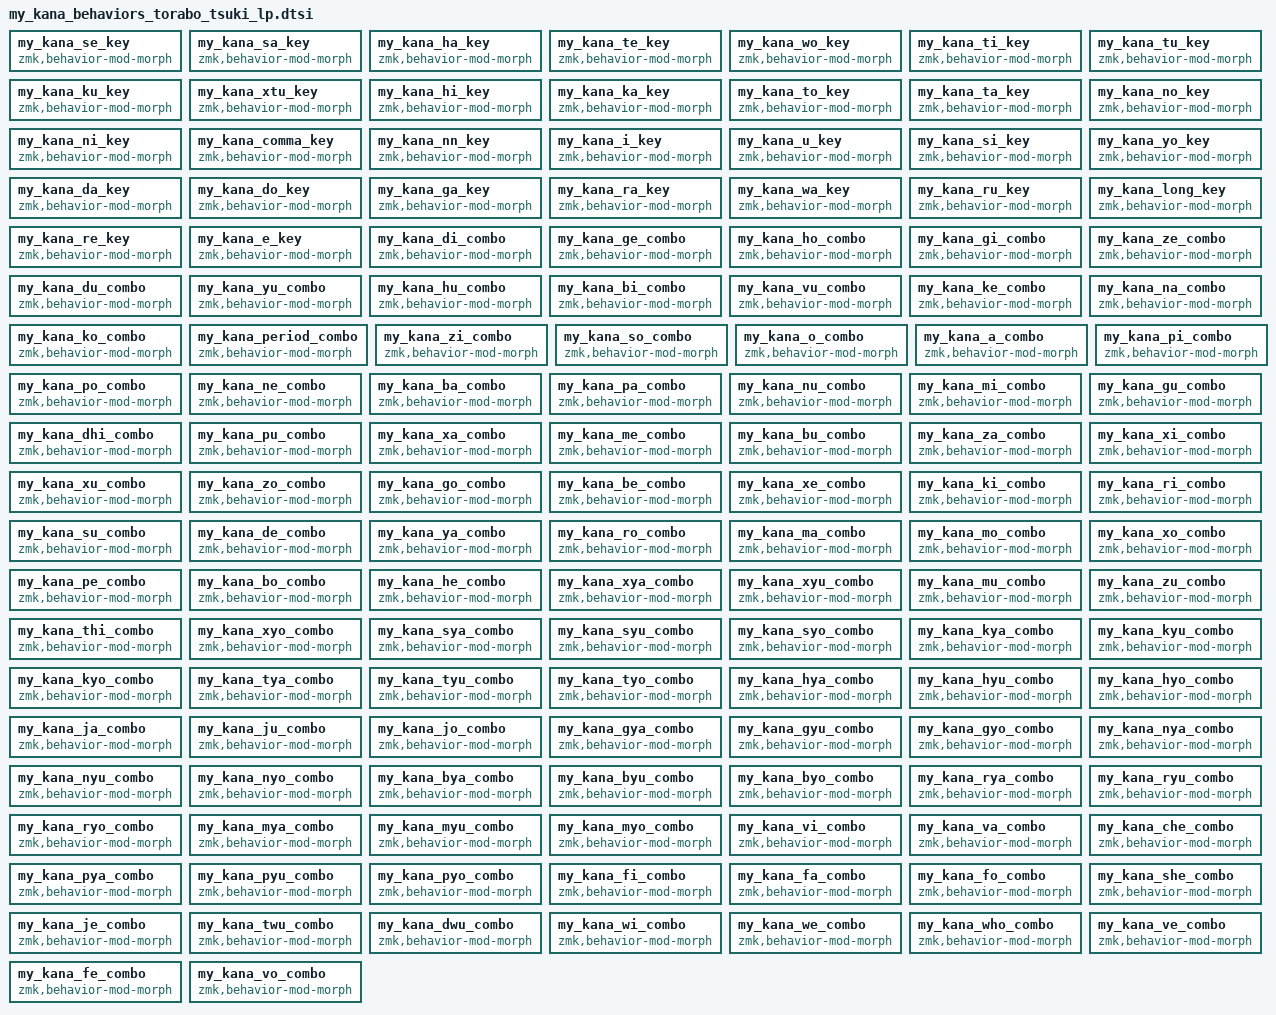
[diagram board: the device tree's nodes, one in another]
// Generated by tools/generate_my_kana_zmk.py. Do not edit manually.

        my_kana_se_key: my_kana_se_key {
            compatible = "zmk,behavior-mod-morph";
            #binding-cells = <0>;
            bindings = <&my_kana_se>, <&kp Q>;
            mods = <MY_KANA_MODS>;
            keep-mods = <MY_KANA_MODS>;
        };

        my_kana_sa_key: my_kana_sa_key {
            compatible = "zmk,behavior-mod-morph";
            #binding-cells = <0>;
            bindings = <&my_kana_sa>, <&kp W>;
            mods = <MY_KANA_MODS>;
            keep-mods = <MY_KANA_MODS>;
        };

        my_kana_ha_key: my_kana_ha_key {
            compatible = "zmk,behavior-mod-morph";
            #binding-cells = <0>;
            bindings = <&my_kana_ha>, <&kp E>;
            mods = <MY_KANA_MODS>;
            keep-mods = <MY_KANA_MODS>;
        };

        my_kana_te_key: my_kana_te_key {
            compatible = "zmk,behavior-mod-morph";
            #binding-cells = <0>;
            bindings = <&my_kana_te>, <&kp R>;
            mods = <MY_KANA_MODS>;
            keep-mods = <MY_KANA_MODS>;
        };

        my_kana_wo_key: my_kana_wo_key {
            compatible = "zmk,behavior-mod-morph";
            #binding-cells = <0>;
            bindings = <&my_kana_wo>, <&kp T>;
            mods = <MY_KANA_MODS>;
            keep-mods = <MY_KANA_MODS>;
        };

        my_kana_ti_key: my_kana_ti_key {
            compatible = "zmk,behavior-mod-morph";
            #binding-cells = <0>;
            bindings = <&my_kana_ti>, <&kp Y>;
            mods = <MY_KANA_MODS>;
            keep-mods = <MY_KANA_MODS>;
        };

        my_kana_tu_key: my_kana_tu_key {
            compatible = "zmk,behavior-mod-morph";
            #binding-cells = <0>;
            bindings = <&my_kana_tu>, <&kp U>;
            mods = <MY_KANA_MODS>;
            keep-mods = <MY_KANA_MODS>;
        };

        my_kana_ku_key: my_kana_ku_key {
            compatible = "zmk,behavior-mod-morph";
            #binding-cells = <0>;
            bindings = <&my_kana_ku>, <&kp I>;
            mods = <MY_KANA_MODS>;
            keep-mods = <MY_KANA_MODS>;
        };

        my_kana_xtu_key: my_kana_xtu_key {
            compatible = "zmk,behavior-mod-morph";
            #binding-cells = <0>;
            bindings = <&my_kana_xtu>, <&kp O>;
            mods = <MY_KANA_MODS>;
            keep-mods = <MY_KANA_MODS>;
        };

        my_kana_hi_key: my_kana_hi_key {
            compatible = "zmk,behavior-mod-morph";
            #binding-cells = <0>;
            bindings = <&my_kana_hi>, <&kp P>;
            mods = <MY_KANA_MODS>;
            keep-mods = <MY_KANA_MODS>;
        };

        my_kana_ka_key: my_kana_ka_key {
            compatible = "zmk,behavior-mod-morph";
            #binding-cells = <0>;
            bindings = <&my_kana_ka>, <&kp A>;
            mods = <MY_KANA_MODS>;
            keep-mods = <MY_KANA_MODS>;
        };

        my_kana_to_key: my_kana_to_key {
            compatible = "zmk,behavior-mod-morph";
            #binding-cells = <0>;
            bindings = <&my_kana_to>, <&kp S>;
            mods = <MY_KANA_MODS>;
            keep-mods = <MY_KANA_MODS>;
        };

        my_kana_ta_key: my_kana_ta_key {
            compatible = "zmk,behavior-mod-morph";
            #binding-cells = <0>;
            bindings = <&my_kana_ta>, <&kp D>;
            mods = <MY_KANA_MODS>;
            keep-mods = <MY_KANA_MODS>;
        };

        my_kana_no_key: my_kana_no_key {
            compatible = "zmk,behavior-mod-morph";
            #binding-cells = <0>;
            bindings = <&my_kana_no>, <&kp F>;
            mods = <MY_KANA_MODS>;
            keep-mods = <MY_KANA_MODS>;
        };

        my_kana_ni_key: my_kana_ni_key {
            compatible = "zmk,behavior-mod-morph";
            #binding-cells = <0>;
            bindings = <&my_kana_ni>, <&kp G>;
            mods = <MY_KANA_MODS>;
            keep-mods = <MY_KANA_MODS>;
        };

        my_kana_comma_key: my_kana_comma_key {
            compatible = "zmk,behavior-mod-morph";
            #binding-cells = <0>;
            bindings = <&my_kana_comma>, <&kp H>;
            mods = <MY_KANA_MODS>;
            keep-mods = <MY_KANA_MODS>;
        };

        my_kana_nn_key: my_kana_nn_key {
            compatible = "zmk,behavior-mod-morph";
            #binding-cells = <0>;
            bindings = <&my_kana_nn>, <&kp J>;
            mods = <MY_KANA_MODS>;
            keep-mods = <MY_KANA_MODS>;
        };

        my_kana_i_key: my_kana_i_key {
            compatible = "zmk,behavior-mod-morph";
            #binding-cells = <0>;
            bindings = <&my_kana_i>, <&kp K>;
            mods = <MY_KANA_MODS>;
            keep-mods = <MY_KANA_MODS>;
        };

        my_kana_u_key: my_kana_u_key {
            compatible = "zmk,behavior-mod-morph";
            #binding-cells = <0>;
            bindings = <&my_kana_u>, <&kp L>;
            mods = <MY_KANA_MODS>;
            keep-mods = <MY_KANA_MODS>;
        };

        my_kana_si_key: my_kana_si_key {
            compatible = "zmk,behavior-mod-morph";
            #binding-cells = <0>;
            bindings = <&my_kana_si>, <&kp SEMI>;
            mods = <MY_KANA_MODS>;
            keep-mods = <MY_KANA_MODS>;
        };

        my_kana_yo_key: my_kana_yo_key {
            compatible = "zmk,behavior-mod-morph";
            #binding-cells = <0>;
            bindings = <&my_kana_yo>, <&kp Z>;
            mods = <MY_KANA_MODS>;
            keep-mods = <MY_KANA_MODS>;
        };

        my_kana_da_key: my_kana_da_key {
            compatible = "zmk,behavior-mod-morph";
            #binding-cells = <0>;
            bindings = <&my_kana_da>, <&kp X>;
            mods = <MY_KANA_MODS>;
            keep-mods = <MY_KANA_MODS>;
        };

        my_kana_do_key: my_kana_do_key {
            compatible = "zmk,behavior-mod-morph";
            #binding-cells = <0>;
            bindings = <&my_kana_do>, <&kp C>;
            mods = <MY_KANA_MODS>;
            keep-mods = <MY_KANA_MODS>;
        };

        my_kana_ga_key: my_kana_ga_key {
            compatible = "zmk,behavior-mod-morph";
            #binding-cells = <0>;
            bindings = <&my_kana_ga>, <&kp V>;
            mods = <MY_KANA_MODS>;
            keep-mods = <MY_KANA_MODS>;
        };

        my_kana_ra_key: my_kana_ra_key {
            compatible = "zmk,behavior-mod-morph";
            #binding-cells = <0>;
            bindings = <&my_kana_ra>, <&kp B>;
            mods = <MY_KANA_MODS>;
            keep-mods = <MY_KANA_MODS>;
        };

        my_kana_wa_key: my_kana_wa_key {
            compatible = "zmk,behavior-mod-morph";
            #binding-cells = <0>;
            bindings = <&my_kana_wa>, <&kp N>;
            mods = <MY_KANA_MODS>;
            keep-mods = <MY_KANA_MODS>;
        };

        my_kana_ru_key: my_kana_ru_key {
            compatible = "zmk,behavior-mod-morph";
            #binding-cells = <0>;
            bindings = <&my_kana_ru>, <&kp M>;
            mods = <MY_KANA_MODS>;
            keep-mods = <MY_KANA_MODS>;
        };

        my_kana_long_key: my_kana_long_key {
            compatible = "zmk,behavior-mod-morph";
            #binding-cells = <0>;
            bindings = <&my_kana_long>, <&kp COMMA>;
            mods = <MY_KANA_MODS>;
            keep-mods = <MY_KANA_MODS>;
        };

        my_kana_re_key: my_kana_re_key {
            compatible = "zmk,behavior-mod-morph";
            #binding-cells = <0>;
            bindings = <&my_kana_re>, <&kp DOT>;
            mods = <MY_KANA_MODS>;
            keep-mods = <MY_KANA_MODS>;
        };

        my_kana_e_key: my_kana_e_key {
            compatible = "zmk,behavior-mod-morph";
            #binding-cells = <0>;
            bindings = <&my_kana_e>, <&kp SLASH>;
            mods = <MY_KANA_MODS>;
            keep-mods = <MY_KANA_MODS>;
        };

        my_kana_di_combo: my_kana_di_combo {
            compatible = "zmk,behavior-mod-morph";
            #binding-cells = <0>;
            bindings = <&my_kana_di>, <&my_kana_di_pass>;
            mods = <MY_KANA_MODS>;
            keep-mods = <MY_KANA_MODS>;
        };

        my_kana_ge_combo: my_kana_ge_combo {
            compatible = "zmk,behavior-mod-morph";
            #binding-cells = <0>;
            bindings = <&my_kana_ge>, <&my_kana_ge_pass>;
            mods = <MY_KANA_MODS>;
            keep-mods = <MY_KANA_MODS>;
        };

        my_kana_ho_combo: my_kana_ho_combo {
            compatible = "zmk,behavior-mod-morph";
            #binding-cells = <0>;
            bindings = <&my_kana_ho>, <&my_kana_ho_pass>;
            mods = <MY_KANA_MODS>;
            keep-mods = <MY_KANA_MODS>;
        };

        my_kana_gi_combo: my_kana_gi_combo {
            compatible = "zmk,behavior-mod-morph";
            #binding-cells = <0>;
            bindings = <&my_kana_gi>, <&my_kana_gi_pass>;
            mods = <MY_KANA_MODS>;
            keep-mods = <MY_KANA_MODS>;
        };

        my_kana_ze_combo: my_kana_ze_combo {
            compatible = "zmk,behavior-mod-morph";
            #binding-cells = <0>;
            bindings = <&my_kana_ze>, <&my_kana_ze_pass>;
            mods = <MY_KANA_MODS>;
            keep-mods = <MY_KANA_MODS>;
        };

        my_kana_du_combo: my_kana_du_combo {
            compatible = "zmk,behavior-mod-morph";
            #binding-cells = <0>;
            bindings = <&my_kana_du>, <&my_kana_du_pass>;
            mods = <MY_KANA_MODS>;
            keep-mods = <MY_KANA_MODS>;
        };

        my_kana_yu_combo: my_kana_yu_combo {
            compatible = "zmk,behavior-mod-morph";
            #binding-cells = <0>;
            bindings = <&my_kana_yu>, <&my_kana_yu_pass>;
            mods = <MY_KANA_MODS>;
            keep-mods = <MY_KANA_MODS>;
        };

        my_kana_hu_combo: my_kana_hu_combo {
            compatible = "zmk,behavior-mod-morph";
            #binding-cells = <0>;
            bindings = <&my_kana_hu>, <&my_kana_hu_pass>;
            mods = <MY_KANA_MODS>;
            keep-mods = <MY_KANA_MODS>;
        };

        my_kana_bi_combo: my_kana_bi_combo {
            compatible = "zmk,behavior-mod-morph";
            #binding-cells = <0>;
            bindings = <&my_kana_bi>, <&my_kana_bi_pass>;
            mods = <MY_KANA_MODS>;
            keep-mods = <MY_KANA_MODS>;
        };

        my_kana_vu_combo: my_kana_vu_combo {
            compatible = "zmk,behavior-mod-morph";
            #binding-cells = <0>;
            bindings = <&my_kana_vu>, <&my_kana_vu_pass>;
            mods = <MY_KANA_MODS>;
            keep-mods = <MY_KANA_MODS>;
        };

        my_kana_ke_combo: my_kana_ke_combo {
            compatible = "zmk,behavior-mod-morph";
            #binding-cells = <0>;
            bindings = <&my_kana_ke>, <&my_kana_ke_pass>;
            mods = <MY_KANA_MODS>;
            keep-mods = <MY_KANA_MODS>;
        };

        my_kana_na_combo: my_kana_na_combo {
            compatible = "zmk,behavior-mod-morph";
            #binding-cells = <0>;
            bindings = <&my_kana_na>, <&my_kana_na_pass>;
            mods = <MY_KANA_MODS>;
            keep-mods = <MY_KANA_MODS>;
        };

        my_kana_ko_combo: my_kana_ko_combo {
            compatible = "zmk,behavior-mod-morph";
            #binding-cells = <0>;
            bindings = <&my_kana_ko>, <&my_kana_ko_pass>;
            mods = <MY_KANA_MODS>;
            keep-mods = <MY_KANA_MODS>;
        };

        my_kana_period_combo: my_kana_period_combo {
            compatible = "zmk,behavior-mod-morph";
            #binding-cells = <0>;
            bindings = <&my_kana_period>, <&my_kana_period_pass>;
            mods = <MY_KANA_MODS>;
            keep-mods = <MY_KANA_MODS>;
        };

        my_kana_zi_combo: my_kana_zi_combo {
            compatible = "zmk,behavior-mod-morph";
            #binding-cells = <0>;
            bindings = <&my_kana_zi>, <&my_kana_zi_pass>;
            mods = <MY_KANA_MODS>;
            keep-mods = <MY_KANA_MODS>;
        };

        my_kana_so_combo: my_kana_so_combo {
            compatible = "zmk,behavior-mod-morph";
            #binding-cells = <0>;
            bindings = <&my_kana_so>, <&my_kana_so_pass>;
            mods = <MY_KANA_MODS>;
            keep-mods = <MY_KANA_MODS>;
        };

        my_kana_o_combo: my_kana_o_combo {
            compatible = "zmk,behavior-mod-morph";
            #binding-cells = <0>;
            bindings = <&my_kana_o>, <&my_kana_o_pass>;
            mods = <MY_KANA_MODS>;
            keep-mods = <MY_KANA_MODS>;
        };

        my_kana_a_combo: my_kana_a_combo {
            compatible = "zmk,behavior-mod-morph";
            #binding-cells = <0>;
            bindings = <&my_kana_a>, <&my_kana_a_pass>;
            mods = <MY_KANA_MODS>;
            keep-mods = <MY_KANA_MODS>;
        };

        my_kana_pi_combo: my_kana_pi_combo {
            compatible = "zmk,behavior-mod-morph";
            #binding-cells = <0>;
            bindings = <&my_kana_pi>, <&my_kana_pi_pass>;
            mods = <MY_KANA_MODS>;
            keep-mods = <MY_KANA_MODS>;
        };

        my_kana_po_combo: my_kana_po_combo {
            compatible = "zmk,behavior-mod-morph";
            #binding-cells = <0>;
            bindings = <&my_kana_po>, <&my_kana_po_pass>;
            mods = <MY_KANA_MODS>;
            keep-mods = <MY_KANA_MODS>;
        };

        my_kana_ne_combo: my_kana_ne_combo {
            compatible = "zmk,behavior-mod-morph";
            #binding-cells = <0>;
            bindings = <&my_kana_ne>, <&my_kana_ne_pass>;
            mods = <MY_KANA_MODS>;
            keep-mods = <MY_KANA_MODS>;
        };

        my_kana_ba_combo: my_kana_ba_combo {
            compatible = "zmk,behavior-mod-morph";
            #binding-cells = <0>;
            bindings = <&my_kana_ba>, <&my_kana_ba_pass>;
            mods = <MY_KANA_MODS>;
            keep-mods = <MY_KANA_MODS>;
        };

        my_kana_pa_combo: my_kana_pa_combo {
            compatible = "zmk,behavior-mod-morph";
            #binding-cells = <0>;
            bindings = <&my_kana_pa>, <&my_kana_pa_pass>;
            mods = <MY_KANA_MODS>;
            keep-mods = <MY_KANA_MODS>;
        };

        my_kana_nu_combo: my_kana_nu_combo {
            compatible = "zmk,behavior-mod-morph";
            #binding-cells = <0>;
            bindings = <&my_kana_nu>, <&my_kana_nu_pass>;
            mods = <MY_KANA_MODS>;
            keep-mods = <MY_KANA_MODS>;
        };

        my_kana_mi_combo: my_kana_mi_combo {
            compatible = "zmk,behavior-mod-morph";
            #binding-cells = <0>;
            bindings = <&my_kana_mi>, <&my_kana_mi_pass>;
            mods = <MY_KANA_MODS>;
            keep-mods = <MY_KANA_MODS>;
        };

        my_kana_gu_combo: my_kana_gu_combo {
            compatible = "zmk,behavior-mod-morph";
            #binding-cells = <0>;
            bindings = <&my_kana_gu>, <&my_kana_gu_pass>;
            mods = <MY_KANA_MODS>;
            keep-mods = <MY_KANA_MODS>;
        };

        my_kana_dhi_combo: my_kana_dhi_combo {
            compatible = "zmk,behavior-mod-morph";
            #binding-cells = <0>;
            bindings = <&my_kana_dhi>, <&my_kana_dhi_pass>;
            mods = <MY_KANA_MODS>;
            keep-mods = <MY_KANA_MODS>;
        };

        my_kana_pu_combo: my_kana_pu_combo {
            compatible = "zmk,behavior-mod-morph";
            #binding-cells = <0>;
            bindings = <&my_kana_pu>, <&my_kana_pu_pass>;
            mods = <MY_KANA_MODS>;
            keep-mods = <MY_KANA_MODS>;
        };

        my_kana_xa_combo: my_kana_xa_combo {
            compatible = "zmk,behavior-mod-morph";
            #binding-cells = <0>;
            bindings = <&my_kana_xa>, <&my_kana_xa_pass>;
            mods = <MY_KANA_MODS>;
            keep-mods = <MY_KANA_MODS>;
        };

        my_kana_me_combo: my_kana_me_combo {
            compatible = "zmk,behavior-mod-morph";
            #binding-cells = <0>;
            bindings = <&my_kana_me>, <&my_kana_me_pass>;
            mods = <MY_KANA_MODS>;
            keep-mods = <MY_KANA_MODS>;
        };

        my_kana_bu_combo: my_kana_bu_combo {
            compatible = "zmk,behavior-mod-morph";
            #binding-cells = <0>;
            bindings = <&my_kana_bu>, <&my_kana_bu_pass>;
            mods = <MY_KANA_MODS>;
            keep-mods = <MY_KANA_MODS>;
        };

        my_kana_za_combo: my_kana_za_combo {
            compatible = "zmk,behavior-mod-morph";
            #binding-cells = <0>;
            bindings = <&my_kana_za>, <&my_kana_za_pass>;
            mods = <MY_KANA_MODS>;
            keep-mods = <MY_KANA_MODS>;
        };

        my_kana_xi_combo: my_kana_xi_combo {
            compatible = "zmk,behavior-mod-morph";
            #binding-cells = <0>;
            bindings = <&my_kana_xi>, <&my_kana_xi_pass>;
            mods = <MY_KANA_MODS>;
            keep-mods = <MY_KANA_MODS>;
        };

        my_kana_xu_combo: my_kana_xu_combo {
            compatible = "zmk,behavior-mod-morph";
            #binding-cells = <0>;
            bindings = <&my_kana_xu>, <&my_kana_xu_pass>;
            mods = <MY_KANA_MODS>;
            keep-mods = <MY_KANA_MODS>;
        };

        my_kana_zo_combo: my_kana_zo_combo {
            compatible = "zmk,behavior-mod-morph";
            #binding-cells = <0>;
            bindings = <&my_kana_zo>, <&my_kana_zo_pass>;
            mods = <MY_KANA_MODS>;
            keep-mods = <MY_KANA_MODS>;
        };

        my_kana_go_combo: my_kana_go_combo {
            compatible = "zmk,behavior-mod-morph";
            #binding-cells = <0>;
            bindings = <&my_kana_go>, <&my_kana_go_pass>;
            mods = <MY_KANA_MODS>;
            keep-mods = <MY_KANA_MODS>;
        };

        my_kana_be_combo: my_kana_be_combo {
            compatible = "zmk,behavior-mod-morph";
            #binding-cells = <0>;
            bindings = <&my_kana_be>, <&my_kana_be_pass>;
            mods = <MY_KANA_MODS>;
            keep-mods = <MY_KANA_MODS>;
        };

        my_kana_xe_combo: my_kana_xe_combo {
            compatible = "zmk,behavior-mod-morph";
            #binding-cells = <0>;
            bindings = <&my_kana_xe>, <&my_kana_xe_pass>;
            mods = <MY_KANA_MODS>;
            keep-mods = <MY_KANA_MODS>;
        };

        my_kana_ki_combo: my_kana_ki_combo {
            compatible = "zmk,behavior-mod-morph";
            #binding-cells = <0>;
            bindings = <&my_kana_ki>, <&my_kana_ki_pass>;
            mods = <MY_KANA_MODS>;
            keep-mods = <MY_KANA_MODS>;
        };

        my_kana_ri_combo: my_kana_ri_combo {
            compatible = "zmk,behavior-mod-morph";
            #binding-cells = <0>;
            bindings = <&my_kana_ri>, <&my_kana_ri_pass>;
            mods = <MY_KANA_MODS>;
            keep-mods = <MY_KANA_MODS>;
        };

        my_kana_su_combo: my_kana_su_combo {
            compatible = "zmk,behavior-mod-morph";
            #binding-cells = <0>;
            bindings = <&my_kana_su>, <&my_kana_su_pass>;
            mods = <MY_KANA_MODS>;
            keep-mods = <MY_KANA_MODS>;
        };

        my_kana_de_combo: my_kana_de_combo {
            compatible = "zmk,behavior-mod-morph";
            #binding-cells = <0>;
            bindings = <&my_kana_de>, <&my_kana_de_pass>;
            mods = <MY_KANA_MODS>;
            keep-mods = <MY_KANA_MODS>;
        };

        my_kana_ya_combo: my_kana_ya_combo {
            compatible = "zmk,behavior-mod-morph";
            #binding-cells = <0>;
            bindings = <&my_kana_ya>, <&my_kana_ya_pass>;
            mods = <MY_KANA_MODS>;
            keep-mods = <MY_KANA_MODS>;
        };

        my_kana_ro_combo: my_kana_ro_combo {
            compatible = "zmk,behavior-mod-morph";
            #binding-cells = <0>;
            bindings = <&my_kana_ro>, <&my_kana_ro_pass>;
            mods = <MY_KANA_MODS>;
            keep-mods = <MY_KANA_MODS>;
        };

        my_kana_ma_combo: my_kana_ma_combo {
            compatible = "zmk,behavior-mod-morph";
            #binding-cells = <0>;
            bindings = <&my_kana_ma>, <&my_kana_ma_pass>;
            mods = <MY_KANA_MODS>;
            keep-mods = <MY_KANA_MODS>;
        };

        my_kana_mo_combo: my_kana_mo_combo {
            compatible = "zmk,behavior-mod-morph";
            #binding-cells = <0>;
            bindings = <&my_kana_mo>, <&my_kana_mo_pass>;
            mods = <MY_KANA_MODS>;
            keep-mods = <MY_KANA_MODS>;
        };

        my_kana_xo_combo: my_kana_xo_combo {
            compatible = "zmk,behavior-mod-morph";
            #binding-cells = <0>;
            bindings = <&my_kana_xo>, <&my_kana_xo_pass>;
            mods = <MY_KANA_MODS>;
            keep-mods = <MY_KANA_MODS>;
        };

        my_kana_pe_combo: my_kana_pe_combo {
            compatible = "zmk,behavior-mod-morph";
            #binding-cells = <0>;
            bindings = <&my_kana_pe>, <&my_kana_pe_pass>;
            mods = <MY_KANA_MODS>;
            keep-mods = <MY_KANA_MODS>;
        };

        my_kana_bo_combo: my_kana_bo_combo {
            compatible = "zmk,behavior-mod-morph";
            #binding-cells = <0>;
            bindings = <&my_kana_bo>, <&my_kana_bo_pass>;
            mods = <MY_KANA_MODS>;
            keep-mods = <MY_KANA_MODS>;
        };

        my_kana_he_combo: my_kana_he_combo {
            compatible = "zmk,behavior-mod-morph";
            #binding-cells = <0>;
            bindings = <&my_kana_he>, <&my_kana_he_pass>;
            mods = <MY_KANA_MODS>;
            keep-mods = <MY_KANA_MODS>;
        };

        my_kana_xya_combo: my_kana_xya_combo {
            compatible = "zmk,behavior-mod-morph";
            #binding-cells = <0>;
            bindings = <&my_kana_xya>, <&my_kana_xya_pass>;
            mods = <MY_KANA_MODS>;
            keep-mods = <MY_KANA_MODS>;
        };

        my_kana_xyu_combo: my_kana_xyu_combo {
            compatible = "zmk,behavior-mod-morph";
            #binding-cells = <0>;
            bindings = <&my_kana_xyu>, <&my_kana_xyu_pass>;
            mods = <MY_KANA_MODS>;
            keep-mods = <MY_KANA_MODS>;
        };

        my_kana_mu_combo: my_kana_mu_combo {
            compatible = "zmk,behavior-mod-morph";
            #binding-cells = <0>;
            bindings = <&my_kana_mu>, <&my_kana_mu_pass>;
            mods = <MY_KANA_MODS>;
            keep-mods = <MY_KANA_MODS>;
        };

        my_kana_zu_combo: my_kana_zu_combo {
            compatible = "zmk,behavior-mod-morph";
            #binding-cells = <0>;
            bindings = <&my_kana_zu>, <&my_kana_zu_pass>;
            mods = <MY_KANA_MODS>;
            keep-mods = <MY_KANA_MODS>;
        };

        my_kana_thi_combo: my_kana_thi_combo {
            compatible = "zmk,behavior-mod-morph";
            #binding-cells = <0>;
            bindings = <&my_kana_thi>, <&my_kana_thi_pass>;
            mods = <MY_KANA_MODS>;
            keep-mods = <MY_KANA_MODS>;
        };

        my_kana_xyo_combo: my_kana_xyo_combo {
            compatible = "zmk,behavior-mod-morph";
            #binding-cells = <0>;
            bindings = <&my_kana_xyo>, <&my_kana_xyo_pass>;
            mods = <MY_KANA_MODS>;
            keep-mods = <MY_KANA_MODS>;
        };

        my_kana_sya_combo: my_kana_sya_combo {
            compatible = "zmk,behavior-mod-morph";
            #binding-cells = <0>;
            bindings = <&my_kana_sya>, <&my_kana_sya_pass>;
            mods = <MY_KANA_MODS>;
            keep-mods = <MY_KANA_MODS>;
        };

        my_kana_syu_combo: my_kana_syu_combo {
            compatible = "zmk,behavior-mod-morph";
            #binding-cells = <0>;
            bindings = <&my_kana_syu>, <&my_kana_syu_pass>;
            mods = <MY_KANA_MODS>;
            keep-mods = <MY_KANA_MODS>;
        };

        my_kana_syo_combo: my_kana_syo_combo {
            compatible = "zmk,behavior-mod-morph";
            #binding-cells = <0>;
            bindings = <&my_kana_syo>, <&my_kana_syo_pass>;
            mods = <MY_KANA_MODS>;
            keep-mods = <MY_KANA_MODS>;
        };

        my_kana_kya_combo: my_kana_kya_combo {
            compatible = "zmk,behavior-mod-morph";
            #binding-cells = <0>;
            bindings = <&my_kana_kya>, <&my_kana_kya_pass>;
            mods = <MY_KANA_MODS>;
            keep-mods = <MY_KANA_MODS>;
        };

        my_kana_kyu_combo: my_kana_kyu_combo {
            compatible = "zmk,behavior-mod-morph";
            #binding-cells = <0>;
            bindings = <&my_kana_kyu>, <&my_kana_kyu_pass>;
            mods = <MY_KANA_MODS>;
            keep-mods = <MY_KANA_MODS>;
        };

        my_kana_kyo_combo: my_kana_kyo_combo {
            compatible = "zmk,behavior-mod-morph";
            #binding-cells = <0>;
            bindings = <&my_kana_kyo>, <&my_kana_kyo_pass>;
            mods = <MY_KANA_MODS>;
            keep-mods = <MY_KANA_MODS>;
        };

        my_kana_tya_combo: my_kana_tya_combo {
            compatible = "zmk,behavior-mod-morph";
            #binding-cells = <0>;
            bindings = <&my_kana_tya>, <&my_kana_tya_pass>;
            mods = <MY_KANA_MODS>;
            keep-mods = <MY_KANA_MODS>;
        };

        my_kana_tyu_combo: my_kana_tyu_combo {
            compatible = "zmk,behavior-mod-morph";
            #binding-cells = <0>;
            bindings = <&my_kana_tyu>, <&my_kana_tyu_pass>;
            mods = <MY_KANA_MODS>;
            keep-mods = <MY_KANA_MODS>;
        };

        my_kana_tyo_combo: my_kana_tyo_combo {
            compatible = "zmk,behavior-mod-morph";
            #binding-cells = <0>;
            bindings = <&my_kana_tyo>, <&my_kana_tyo_pass>;
            mods = <MY_KANA_MODS>;
            keep-mods = <MY_KANA_MODS>;
        };

        my_kana_hya_combo: my_kana_hya_combo {
            compatible = "zmk,behavior-mod-morph";
            #binding-cells = <0>;
            bindings = <&my_kana_hya>, <&my_kana_hya_pass>;
            mods = <MY_KANA_MODS>;
            keep-mods = <MY_KANA_MODS>;
        };

        my_kana_hyu_combo: my_kana_hyu_combo {
            compatible = "zmk,behavior-mod-morph";
            #binding-cells = <0>;
            bindings = <&my_kana_hyu>, <&my_kana_hyu_pass>;
            mods = <MY_KANA_MODS>;
            keep-mods = <MY_KANA_MODS>;
        };

        my_kana_hyo_combo: my_kana_hyo_combo {
            compatible = "zmk,behavior-mod-morph";
            #binding-cells = <0>;
            bindings = <&my_kana_hyo>, <&my_kana_hyo_pass>;
            mods = <MY_KANA_MODS>;
            keep-mods = <MY_KANA_MODS>;
        };

        my_kana_ja_combo: my_kana_ja_combo {
            compatible = "zmk,behavior-mod-morph";
            #binding-cells = <0>;
            bindings = <&my_kana_ja>, <&my_kana_ja_pass>;
            mods = <MY_KANA_MODS>;
            keep-mods = <MY_KANA_MODS>;
        };

        my_kana_ju_combo: my_kana_ju_combo {
            compatible = "zmk,behavior-mod-morph";
            #binding-cells = <0>;
            bindings = <&my_kana_ju>, <&my_kana_ju_pass>;
            mods = <MY_KANA_MODS>;
            keep-mods = <MY_KANA_MODS>;
        };

        my_kana_jo_combo: my_kana_jo_combo {
            compatible = "zmk,behavior-mod-morph";
            #binding-cells = <0>;
            bindings = <&my_kana_jo>, <&my_kana_jo_pass>;
            mods = <MY_KANA_MODS>;
            keep-mods = <MY_KANA_MODS>;
        };

        my_kana_gya_combo: my_kana_gya_combo {
            compatible = "zmk,behavior-mod-morph";
            #binding-cells = <0>;
            bindings = <&my_kana_gya>, <&my_kana_gya_pass>;
            mods = <MY_KANA_MODS>;
            keep-mods = <MY_KANA_MODS>;
        };

        my_kana_gyu_combo: my_kana_gyu_combo {
            compatible = "zmk,behavior-mod-morph";
            #binding-cells = <0>;
            bindings = <&my_kana_gyu>, <&my_kana_gyu_pass>;
            mods = <MY_KANA_MODS>;
            keep-mods = <MY_KANA_MODS>;
        };

        my_kana_gyo_combo: my_kana_gyo_combo {
            compatible = "zmk,behavior-mod-morph";
            #binding-cells = <0>;
            bindings = <&my_kana_gyo>, <&my_kana_gyo_pass>;
            mods = <MY_KANA_MODS>;
            keep-mods = <MY_KANA_MODS>;
        };

        my_kana_nya_combo: my_kana_nya_combo {
            compatible = "zmk,behavior-mod-morph";
            #binding-cells = <0>;
            bindings = <&my_kana_nya>, <&my_kana_nya_pass>;
            mods = <MY_KANA_MODS>;
            keep-mods = <MY_KANA_MODS>;
        };

        my_kana_nyu_combo: my_kana_nyu_combo {
            compatible = "zmk,behavior-mod-morph";
            #binding-cells = <0>;
            bindings = <&my_kana_nyu>, <&my_kana_nyu_pass>;
            mods = <MY_KANA_MODS>;
            keep-mods = <MY_KANA_MODS>;
        };

        my_kana_nyo_combo: my_kana_nyo_combo {
            compatible = "zmk,behavior-mod-morph";
            #binding-cells = <0>;
            bindings = <&my_kana_nyo>, <&my_kana_nyo_pass>;
            mods = <MY_KANA_MODS>;
            keep-mods = <MY_KANA_MODS>;
        };

        my_kana_bya_combo: my_kana_bya_combo {
            compatible = "zmk,behavior-mod-morph";
            #binding-cells = <0>;
            bindings = <&my_kana_bya>, <&my_kana_bya_pass>;
            mods = <MY_KANA_MODS>;
            keep-mods = <MY_KANA_MODS>;
        };

        my_kana_byu_combo: my_kana_byu_combo {
            compatible = "zmk,behavior-mod-morph";
            #binding-cells = <0>;
            bindings = <&my_kana_byu>, <&my_kana_byu_pass>;
            mods = <MY_KANA_MODS>;
            keep-mods = <MY_KANA_MODS>;
        };

        my_kana_byo_combo: my_kana_byo_combo {
            compatible = "zmk,behavior-mod-morph";
            #binding-cells = <0>;
            bindings = <&my_kana_byo>, <&my_kana_byo_pass>;
            mods = <MY_KANA_MODS>;
            keep-mods = <MY_KANA_MODS>;
        };

        my_kana_rya_combo: my_kana_rya_combo {
            compatible = "zmk,behavior-mod-morph";
            #binding-cells = <0>;
            bindings = <&my_kana_rya>, <&my_kana_rya_pass>;
            mods = <MY_KANA_MODS>;
            keep-mods = <MY_KANA_MODS>;
        };

        my_kana_ryu_combo: my_kana_ryu_combo {
            compatible = "zmk,behavior-mod-morph";
            #binding-cells = <0>;
            bindings = <&my_kana_ryu>, <&my_kana_ryu_pass>;
            mods = <MY_KANA_MODS>;
            keep-mods = <MY_KANA_MODS>;
        };

        my_kana_ryo_combo: my_kana_ryo_combo {
            compatible = "zmk,behavior-mod-morph";
            #binding-cells = <0>;
            bindings = <&my_kana_ryo>, <&my_kana_ryo_pass>;
            mods = <MY_KANA_MODS>;
            keep-mods = <MY_KANA_MODS>;
        };

        my_kana_mya_combo: my_kana_mya_combo {
            compatible = "zmk,behavior-mod-morph";
            #binding-cells = <0>;
            bindings = <&my_kana_mya>, <&my_kana_mya_pass>;
            mods = <MY_KANA_MODS>;
            keep-mods = <MY_KANA_MODS>;
        };

        my_kana_myu_combo: my_kana_myu_combo {
            compatible = "zmk,behavior-mod-morph";
            #binding-cells = <0>;
            bindings = <&my_kana_myu>, <&my_kana_myu_pass>;
            mods = <MY_KANA_MODS>;
            keep-mods = <MY_KANA_MODS>;
        };

        my_kana_myo_combo: my_kana_myo_combo {
            compatible = "zmk,behavior-mod-morph";
            #binding-cells = <0>;
            bindings = <&my_kana_myo>, <&my_kana_myo_pass>;
            mods = <MY_KANA_MODS>;
            keep-mods = <MY_KANA_MODS>;
        };

        my_kana_vi_combo: my_kana_vi_combo {
            compatible = "zmk,behavior-mod-morph";
            #binding-cells = <0>;
            bindings = <&my_kana_vi>, <&my_kana_vi_pass>;
            mods = <MY_KANA_MODS>;
            keep-mods = <MY_KANA_MODS>;
        };

        my_kana_va_combo: my_kana_va_combo {
            compatible = "zmk,behavior-mod-morph";
            #binding-cells = <0>;
            bindings = <&my_kana_va>, <&my_kana_va_pass>;
            mods = <MY_KANA_MODS>;
            keep-mods = <MY_KANA_MODS>;
        };

        my_kana_che_combo: my_kana_che_combo {
            compatible = "zmk,behavior-mod-morph";
            #binding-cells = <0>;
            bindings = <&my_kana_che>, <&my_kana_che_pass>;
            mods = <MY_KANA_MODS>;
            keep-mods = <MY_KANA_MODS>;
        };

        my_kana_pya_combo: my_kana_pya_combo {
            compatible = "zmk,behavior-mod-morph";
            #binding-cells = <0>;
            bindings = <&my_kana_pya>, <&my_kana_pya_pass>;
            mods = <MY_KANA_MODS>;
            keep-mods = <MY_KANA_MODS>;
        };

        my_kana_pyu_combo: my_kana_pyu_combo {
            compatible = "zmk,behavior-mod-morph";
            #binding-cells = <0>;
            bindings = <&my_kana_pyu>, <&my_kana_pyu_pass>;
            mods = <MY_KANA_MODS>;
            keep-mods = <MY_KANA_MODS>;
        };

        my_kana_pyo_combo: my_kana_pyo_combo {
            compatible = "zmk,behavior-mod-morph";
            #binding-cells = <0>;
            bindings = <&my_kana_pyo>, <&my_kana_pyo_pass>;
            mods = <MY_KANA_MODS>;
            keep-mods = <MY_KANA_MODS>;
        };

        my_kana_fi_combo: my_kana_fi_combo {
            compatible = "zmk,behavior-mod-morph";
            #binding-cells = <0>;
            bindings = <&my_kana_fi>, <&my_kana_fi_pass>;
            mods = <MY_KANA_MODS>;
            keep-mods = <MY_KANA_MODS>;
        };

        my_kana_fa_combo: my_kana_fa_combo {
            compatible = "zmk,behavior-mod-morph";
            #binding-cells = <0>;
            bindings = <&my_kana_fa>, <&my_kana_fa_pass>;
            mods = <MY_KANA_MODS>;
            keep-mods = <MY_KANA_MODS>;
        };

        my_kana_fo_combo: my_kana_fo_combo {
            compatible = "zmk,behavior-mod-morph";
            #binding-cells = <0>;
            bindings = <&my_kana_fo>, <&my_kana_fo_pass>;
            mods = <MY_KANA_MODS>;
            keep-mods = <MY_KANA_MODS>;
        };

        my_kana_she_combo: my_kana_she_combo {
            compatible = "zmk,behavior-mod-morph";
            #binding-cells = <0>;
            bindings = <&my_kana_she>, <&my_kana_she_pass>;
            mods = <MY_KANA_MODS>;
            keep-mods = <MY_KANA_MODS>;
        };

        my_kana_je_combo: my_kana_je_combo {
            compatible = "zmk,behavior-mod-morph";
            #binding-cells = <0>;
            bindings = <&my_kana_je>, <&my_kana_je_pass>;
            mods = <MY_KANA_MODS>;
            keep-mods = <MY_KANA_MODS>;
        };

        my_kana_twu_combo: my_kana_twu_combo {
            compatible = "zmk,behavior-mod-morph";
            #binding-cells = <0>;
            bindings = <&my_kana_twu>, <&my_kana_twu_pass>;
            mods = <MY_KANA_MODS>;
            keep-mods = <MY_KANA_MODS>;
        };

        my_kana_dwu_combo: my_kana_dwu_combo {
            compatible = "zmk,behavior-mod-morph";
            #binding-cells = <0>;
            bindings = <&my_kana_dwu>, <&my_kana_dwu_pass>;
            mods = <MY_KANA_MODS>;
            keep-mods = <MY_KANA_MODS>;
        };

        my_kana_wi_combo: my_kana_wi_combo {
            compatible = "zmk,behavior-mod-morph";
            #binding-cells = <0>;
            bindings = <&my_kana_wi>, <&my_kana_wi_pass>;
            mods = <MY_KANA_MODS>;
            keep-mods = <MY_KANA_MODS>;
        };

        my_kana_we_combo: my_kana_we_combo {
            compatible = "zmk,behavior-mod-morph";
            #binding-cells = <0>;
            bindings = <&my_kana_we>, <&my_kana_we_pass>;
            mods = <MY_KANA_MODS>;
            keep-mods = <MY_KANA_MODS>;
        };

        my_kana_who_combo: my_kana_who_combo {
            compatible = "zmk,behavior-mod-morph";
            #binding-cells = <0>;
            bindings = <&my_kana_who>, <&my_kana_who_pass>;
            mods = <MY_KANA_MODS>;
            keep-mods = <MY_KANA_MODS>;
        };

        my_kana_ve_combo: my_kana_ve_combo {
            compatible = "zmk,behavior-mod-morph";
            #binding-cells = <0>;
            bindings = <&my_kana_ve>, <&my_kana_ve_pass>;
            mods = <MY_KANA_MODS>;
            keep-mods = <MY_KANA_MODS>;
        };

        my_kana_fe_combo: my_kana_fe_combo {
            compatible = "zmk,behavior-mod-morph";
            #binding-cells = <0>;
            bindings = <&my_kana_fe>, <&my_kana_fe_pass>;
            mods = <MY_KANA_MODS>;
            keep-mods = <MY_KANA_MODS>;
        };

        my_kana_vo_combo: my_kana_vo_combo {
            compatible = "zmk,behavior-mod-morph";
            #binding-cells = <0>;
            bindings = <&my_kana_vo>, <&my_kana_vo_pass>;
            mods = <MY_KANA_MODS>;
            keep-mods = <MY_KANA_MODS>;
        };

